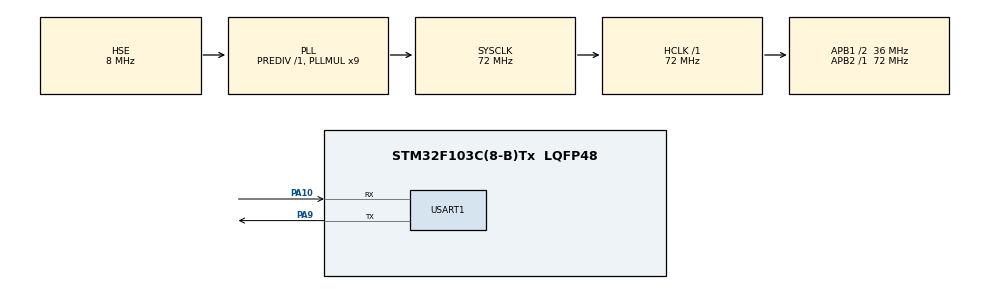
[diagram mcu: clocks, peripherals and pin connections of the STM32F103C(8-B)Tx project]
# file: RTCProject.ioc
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Mcu.Family=STM32F1
Mcu.Name=STM32F103C(8-B)Tx
Mcu.Package=LQFP48
NVIC.PriorityGroup=NVIC_PRIORITYGROUP_4
PA10.Mode=Asynchronous
PA10.Signal=USART1_RX
PA9.Mode=Asynchronous
PA9.Signal=USART1_TX
PC14-OSC32_IN.Mode=LSE-External-Oscillator
PC14-OSC32_IN.Signal=RCC_OSC32_IN
PC15-OSC32_OUT.Mode=LSE-External-Oscillator
PC15-OSC32_OUT.Signal=RCC_OSC32_OUT
PD0-OSC_IN.Mode=HSE-External-Oscillator
PD0-OSC_IN.Signal=RCC_OSC_IN
PD1-OSC_OUT.Mode=HSE-External-Oscillator
PD1-OSC_OUT.Signal=RCC_OSC_OUT
ProjectManager.HeapSize=0x200
ProjectManager.StackSize=0x400
ProjectManager.TargetToolchain=MDK-ARM V5
RCC.AHBFreq_Value=72000000
RCC.APB1CLKDivider=RCC_HCLK_DIV2
RCC.APB1Freq_Value=36000000
RCC.APB1TimFreq_Value=72000000
RCC.APB2Freq_Value=72000000
RCC.APB2TimFreq_Value=72000000
RCC.HCLKFreq_Value=72000000
RCC.PLLMUL=RCC_PLL_MUL9
RCC.PLLSourceVirtual=RCC_PLLSOURCE_HSE
RCC.RTCClockSelection=RCC_RTCCLKSOURCE_LSE
RCC.SYSCLKFreq_VALUE=72000000
RCC.SYSCLKSource=RCC_SYSCLKSOURCE_PLLCLK
RCC.USBFreq_Value=72000000
USART1.VirtualMode=VM_ASYNC
VP_RTC_No_RTC_Output.Mode=RTC_OUT_NO
VP_RTC_VS_RTC_Activate.Mode=RTC_Enabled
VP_RTC_VS_RTC_Calendar.Mode=RTC_Calendar
VP_SYS_VS_ND.Mode=No_Debug
board=custom

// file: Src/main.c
/* USER CODE BEGIN Header */
/**
  ******************************************************************************
  * @file           : main.c
  * @brief          : Main program body
  ******************************************************************************
  * @attention
  *
  * <h2><center>&copy; Copyright (c) 2021 STMicroelectronics.
  * All rights reserved.</center></h2>
  *
  * This software component is licensed by ST under BSD 3-Clause license,
  * the "License"; You may not use this file except in compliance with the
  * License. You may obtain a copy of the License at:
  *                        opensource.org/licenses/BSD-3-Clause
  *
  ******************************************************************************
  */
/* USER CODE END Header */
#include "main.h"
#include "rtc.h"
#include "usart.h"
#include "gpio.h"

/* USER CODE BEGIN Includes */

#include <stdio.h>

/* USER CODE END Includes */

/* USER CODE BEGIN PM */

int fputc(int ch,FILE *f)

{
    HAL_UART_Transmit(&huart1,(uint8_t *)&ch,1,0xFFFF);
		//等待发送结束
		while(__HAL_UART_GET_FLAG(&huart1,UART_FLAG_TC)!=SET){
		}

    return ch;
}

/* USER CODE END PM */

void SystemClock_Config(void);

/* USER CODE BEGIN 0 */
RTC_DateTypeDef date;  //获取日期结构体

RTC_TimeTypeDef time;   //获取时间结构体

/* USER CODE END 0 */

int main(void)
{

  /* MCU Configuration--------------------------------------------------------*/

  /* Reset of all peripherals, Initializes the Flash interface and the Systick. */
  HAL_Init();

  /* Configure the system clock */
  SystemClock_Config();

  /* Initialize all configured peripherals */
  MX_GPIO_Init();
  MX_RTC_Init();
  MX_USART1_UART_Init();

  /* Infinite loop */
  /* USER CODE BEGIN WHILE */

	date.Year=21;
	date.Month=11;
	date.Date=29;
	date.WeekDay=RTC_WEEKDAY_FRIDAY;

	time.Hours=20;
    time.Minutes=20;
	time.Seconds=20;

	HAL_RTC_SetDate(&hrtc,&date,RTC_FORMAT_BIN);
	HAL_RTC_SetTime(&hrtc,&time,RTC_FORMAT_BIN);

	while (1)
	{
    /* USER CODE END WHILE */
		HAL_RTC_GetTime(&hrtc, &time, RTC_FORMAT_BIN);
		HAL_RTC_GetDate(&hrtc, &date, RTC_FORMAT_BIN);
		printf("%0004d/%02d/%02d %02d:%02d:%02d\r\n",date.Year+2000,date.Month,date.Date,time.Hours,time.Minutes,time.Seconds);
		HAL_Delay(1000);

	}
}

void SystemClock_Config(void)
{
  RCC_OscInitTypeDef RCC_OscInitStruct = {0};
  RCC_ClkInitTypeDef RCC_ClkInitStruct = {0};
  RCC_PeriphCLKInitTypeDef PeriphClkInit = {0};

  /** Initializes the RCC Oscillators according to the specified parameters
  * in the RCC_OscInitTypeDef structure.
  */
  RCC_OscInitStruct.OscillatorType = RCC_OSCILLATORTYPE_HSE|RCC_OSCILLATORTYPE_LSE;
  RCC_OscInitStruct.HSEState = RCC_HSE_ON;
  RCC_OscInitStruct.HSEPredivValue = RCC_HSE_PREDIV_DIV1;
  RCC_OscInitStruct.LSEState = RCC_LSE_ON;
  RCC_OscInitStruct.HSIState = RCC_HSI_ON;
  RCC_OscInitStruct.PLL.PLLState = RCC_PLL_ON;
  RCC_OscInitStruct.PLL.PLLSource = RCC_PLLSOURCE_HSE;
  RCC_OscInitStruct.PLL.PLLMUL = RCC_PLL_MUL9;
  if (HAL_RCC_OscConfig(&RCC_OscInitStruct) != HAL_OK)
  {
    Error_Handler();
  }
  /** Initializes the CPU, AHB and APB buses clocks
  */
  RCC_ClkInitStruct.ClockType = RCC_CLOCKTYPE_HCLK|RCC_CLOCKTYPE_SYSCLK
                              |RCC_CLOCKTYPE_PCLK1|RCC_CLOCKTYPE_PCLK2;
  RCC_ClkInitStruct.SYSCLKSource = RCC_SYSCLKSOURCE_PLLCLK;
  RCC_ClkInitStruct.AHBCLKDivider = RCC_SYSCLK_DIV1;
  RCC_ClkInitStruct.APB1CLKDivider = RCC_HCLK_DIV2;
  RCC_ClkInitStruct.APB2CLKDivider = RCC_HCLK_DIV1;

  if (HAL_RCC_ClockConfig(&RCC_ClkInitStruct, FLASH_LATENCY_2) != HAL_OK)
  {
    Error_Handler();
  }
  PeriphClkInit.PeriphClockSelection = RCC_PERIPHCLK_RTC;
  PeriphClkInit.RTCClockSelection = RCC_RTCCLKSOURCE_LSE;
  if (HAL_RCCEx_PeriphCLKConfig(&PeriphClkInit) != HAL_OK)
  {
    Error_Handler();
  }
}

void Error_Handler(void)
{
  __disable_irq();
  while (1)
  {
  }
}

/************************ (C) COPYRIGHT STMicroelectronics *****END OF FILE****/
